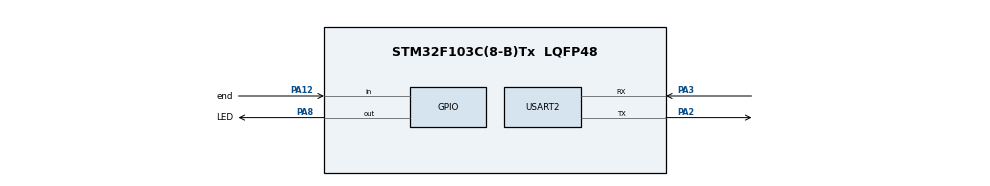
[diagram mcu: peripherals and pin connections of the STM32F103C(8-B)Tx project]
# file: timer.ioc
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Mcu.Family=STM32F1
Mcu.Name=STM32F103C(8-B)Tx
Mcu.Package=LQFP48
NVIC.PriorityGroup=NVIC_PRIORITYGROUP_4
NVIC.USART2_IRQn=true\:0\:0\:false
PA12.GPIO_Label=end
PA12.GPIO_Mode=GPIO_MODE_INPUT
PA12.GPIO_PuPd=GPIO_NOPULL
PA12.Signal=GPIO_Input
PA13.Mode=Serial_Wire
PA13.Signal=SYS_JTMS-SWDIO
PA14.Mode=Serial_Wire
PA14.Signal=SYS_JTCK-SWCLK
PA2.Mode=Asynchronous
PA2.Signal=USART2_TX
PA3.Mode=Asynchronous
PA3.Signal=USART2_RX
PA8.GPIO_Label=LED
PA8.Signal=GPIO_Output
ProjectManager.TargetToolchain=MDK-ARM V5
RCC.APB1Freq_Value=8000000
RCC.APB2Freq_Value=8000000
board=timer

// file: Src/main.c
/**
  ******************************************************************************
  * File Name          : main.c
  * Description        : Main program body
  ******************************************************************************
  *
  * COPYRIGHT(c) 2018 STMicroelectronics
  *
  * Redistribution and use in source and binary forms, with or without modification,
  * are permitted provided that the following conditions are met:
  *   1. Redistributions of source code must retain the above copyright notice,
  *      this list of conditions and the following disclaimer.
  *   2. Redistributions in binary form must reproduce the above copyright notice,
  *      this list of conditions and the following disclaimer in the documentation
  *      and/or other materials provided with the distribution.
  *   3. Neither the name of STMicroelectronics nor the names of its contributors
  *      may be used to endorse or promote products derived from this software
  *      without specific prior written permission.
  *
  * THIS SOFTWARE IS PROVIDED BY THE COPYRIGHT HOLDERS AND CONTRIBUTORS "AS IS"
  * AND ANY EXPRESS OR IMPLIED WARRANTIES, INCLUDING, BUT NOT LIMITED TO, THE
  * IMPLIED WARRANTIES OF MERCHANTABILITY AND FITNESS FOR A PARTICULAR PURPOSE ARE
  * DISCLAIMED. IN NO EVENT SHALL THE COPYRIGHT HOLDER OR CONTRIBUTORS BE LIABLE
  * FOR ANY DIRECT, INDIRECT, INCIDENTAL, SPECIAL, EXEMPLARY, OR CONSEQUENTIAL
  * DAMAGES (INCLUDING, BUT NOT LIMITED TO, PROCUREMENT OF SUBSTITUTE GOODS OR
  * SERVICES; LOSS OF USE, DATA, OR PROFITS; OR BUSINESS INTERRUPTION) HOWEVER
  * CAUSED AND ON ANY THEORY OF LIABILITY, WHETHER IN CONTRACT, STRICT LIABILITY,
  * OR TORT (INCLUDING NEGLIGENCE OR OTHERWISE) ARISING IN ANY WAY OUT OF THE USE
  * OF THIS SOFTWARE, EVEN IF ADVISED OF THE POSSIBILITY OF SUCH DAMAGE.
  *
  ******************************************************************************
  */
#include "stm32f1xx_hal.h"

UART_HandleTypeDef huart2;

/* USER CODE BEGIN PV */
/* Private variables ---------------------------------------------------------*/

/* USER CODE END PV */

void SystemClock_Config(void);
static void MX_GPIO_Init(void);
static void MX_USART2_UART_Init(void);

/* USER CODE BEGIN PFP */
/* Private function prototypes -----------------------------------------------*/

/* USER CODE END PFP */

/* USER CODE BEGIN 0 */

//******UART commucition using IT******\r\nPlease enter 10 characters:
/* USER CODE END 0 */

int main(void)
{

  /* USER CODE BEGIN 1 */
	char stop[4];
	uint16_t start;
	int end;
	char str[20];
	uint32_t start_time;
	uint32_t end_time;
	uint32_t run_time;

  /* USER CODE END 1 */

  /* MCU Configuration----------------------------------------------------------*/

  /* Reset of all peripherals, Initializes the Flash interface and the Systick. */
  HAL_Init();

  /* Configure the system clock */
  SystemClock_Config();

  /* Initialize all configured peripherals */
  MX_GPIO_Init();
  MX_USART2_UART_Init();

  /* Infinite loop */
  while (1)
  {

  }

}

/** System Clock Configuration
*/
void SystemClock_Config(void)
{

  RCC_OscInitTypeDef RCC_OscInitStruct;
  RCC_ClkInitTypeDef RCC_ClkInitStruct;

  RCC_OscInitStruct.OscillatorType = RCC_OSCILLATORTYPE_HSI;
  RCC_OscInitStruct.HSIState = RCC_HSI_ON;
  RCC_OscInitStruct.HSICalibrationValue = 16;
  RCC_OscInitStruct.PLL.PLLState = RCC_PLL_NONE;
  HAL_RCC_OscConfig(&RCC_OscInitStruct);

  RCC_ClkInitStruct.ClockType = RCC_CLOCKTYPE_SYSCLK;
  RCC_ClkInitStruct.SYSCLKSource = RCC_SYSCLKSOURCE_HSI;
  RCC_ClkInitStruct.AHBCLKDivider = RCC_SYSCLK_DIV1;
  RCC_ClkInitStruct.APB1CLKDivider = RCC_HCLK_DIV1;
  RCC_ClkInitStruct.APB2CLKDivider = RCC_HCLK_DIV1;
  HAL_RCC_ClockConfig(&RCC_ClkInitStruct, FLASH_LATENCY_0);

  HAL_SYSTICK_Config(HAL_RCC_GetHCLKFreq()/1000);

  HAL_SYSTICK_CLKSourceConfig(SYSTICK_CLKSOURCE_HCLK);

}

/* USART2 init function */
void MX_USART2_UART_Init(void)
{

  huart2.Instance = USART2;
  huart2.Init.BaudRate = 115200;
  huart2.Init.WordLength = UART_WORDLENGTH_8B;
  huart2.Init.StopBits = UART_STOPBITS_1;
  huart2.Init.Parity = UART_PARITY_NONE;
  huart2.Init.Mode = UART_MODE_TX_RX;
  huart2.Init.HwFlowCtl = UART_HWCONTROL_NONE;
  huart2.Init.OverSampling = UART_OVERSAMPLING_16;
  HAL_UART_Init(&huart2);

}

/** Configure pins as
        * Analog
        * Input
        * Output
        * EVENT_OUT
        * EXTI
*/
void MX_GPIO_Init(void)
{

  GPIO_InitTypeDef GPIO_InitStruct;

  /* GPIO Ports Clock Enable */
  __GPIOA_CLK_ENABLE();

  /*Configure GPIO pin : PA8 */
  GPIO_InitStruct.Pin = GPIO_PIN_8;
  GPIO_InitStruct.Mode = GPIO_MODE_OUTPUT_PP;
  GPIO_InitStruct.Speed = GPIO_SPEED_LOW;
  HAL_GPIO_Init(GPIOA, &GPIO_InitStruct);

  /*Configure GPIO pin : PA12 */
  GPIO_InitStruct.Pin = GPIO_PIN_12;
  GPIO_InitStruct.Mode = GPIO_MODE_INPUT;
  GPIO_InitStruct.Pull = GPIO_NOPULL;
  HAL_GPIO_Init(GPIOA, &GPIO_InitStruct);

}

/************************ (C) COPYRIGHT STMicroelectronics *****END OF FILE****/
